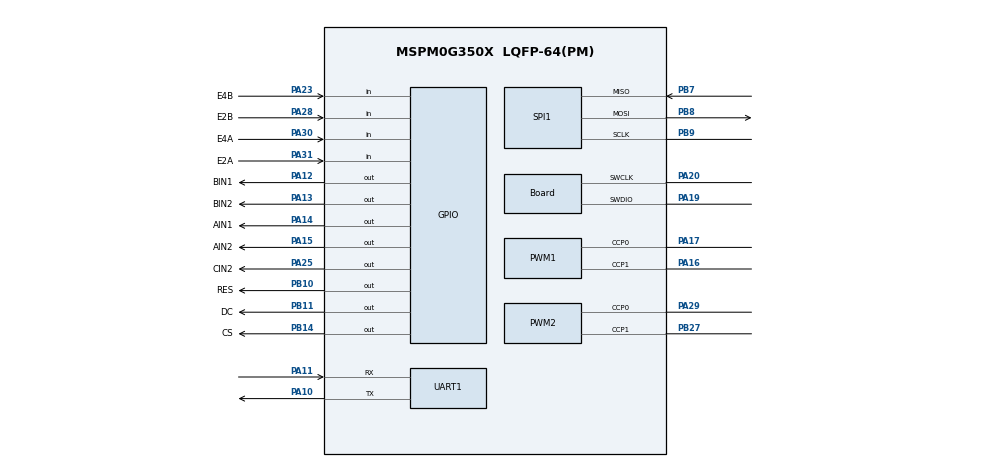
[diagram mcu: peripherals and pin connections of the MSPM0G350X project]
/**
 * @cliArgs --device "MSPM0G350X" --package "LQFP-64(PM)" --part "Default" --product "mspm0_sdk@1.30.00.03"
 * @versions {"tool":"1.19.0+3426"}
 */

/**
 * Import the modules used in this configuration.
 */
const GPIO          = scripting.addModule("/ti/driverlib/GPIO", {}, false);
const GPIO1         = GPIO.addInstance();
const GPIO2         = GPIO.addInstance();
const GPIO3         = GPIO.addInstance();
const GPIO4         = GPIO.addInstance();
const GPIO5         = GPIO.addInstance();
const PWM           = scripting.addModule("/ti/driverlib/PWM", {}, false);
const PWM1          = PWM.addInstance();
const PWM2          = PWM.addInstance();
const SPI           = scripting.addModule("/ti/driverlib/SPI", {}, false);
const SPI1          = SPI.addInstance();
const SYSCTL        = scripting.addModule("/ti/driverlib/SYSCTL");
const TIMER         = scripting.addModule("/ti/driverlib/TIMER", {}, false);
const TIMER1        = TIMER.addInstance();
const UART          = scripting.addModule("/ti/driverlib/UART", {}, false);
const UART1         = UART.addInstance();
const ProjectConfig = scripting.addModule("/ti/project_config/ProjectConfig");

/**
 * Write custom configuration values to the imported modules.
 */
const gate7  = system.clockTree["MFCLKGATE"];
gate7.enable = true;

GPIO1.$name                          = "LED";
GPIO1.associatedPins.create(3);
GPIO1.associatedPins[0].$name        = "LEDR";
GPIO1.associatedPins[0].assignedPort = "PORTB";
GPIO1.associatedPins[0].assignedPin  = "18";
GPIO1.associatedPins[1].$name        = "LEDG";
GPIO1.associatedPins[1].assignedPort = "PORTB";
GPIO1.associatedPins[1].assignedPin  = "19";
GPIO1.associatedPins[2].$name        = "LEDB";
GPIO1.associatedPins[2].assignedPort = "PORTB";
GPIO1.associatedPins[2].assignedPin  = "22";

const Board                       = scripting.addModule("/ti/driverlib/Board", {}, false);
Board.peripheral.$assign          = "DEBUGSS";
Board.peripheral.swclkPin.$assign = "PA20";
Board.peripheral.swdioPin.$assign = "PA19";

GPIO2.$name                          = "KEY";
GPIO2.associatedPins[0].$name        = "KEY1";
GPIO2.associatedPins[0].assignedPort = "PORTB";
GPIO2.associatedPins[0].assignedPin  = "21";
GPIO2.associatedPins[0].direction    = "INPUT";

GPIO3.$name                         = "OLED";
GPIO3.port                          = "PORTB";
GPIO3.associatedPins.create(3);
GPIO3.associatedPins[0].$name       = "RES";
GPIO3.associatedPins[0].ioStructure = "SD";
GPIO3.associatedPins[0].assignedPin = "10";
GPIO3.associatedPins[0].pin.$assign = "PB10";
GPIO3.associatedPins[1].$name       = "DC";
GPIO3.associatedPins[1].ioStructure = "SD";
GPIO3.associatedPins[1].assignedPin = "11";
GPIO3.associatedPins[1].pin.$assign = "PB11";
GPIO3.associatedPins[2].$name       = "CS";
GPIO3.associatedPins[2].ioStructure = "SD";
GPIO3.associatedPins[2].assignedPin = "14";
GPIO3.associatedPins[2].pin.$assign = "PB14";

GPIO4.$name                          = "TB6612";
GPIO4.port                           = "PORTA";
GPIO4.associatedPins.create(8);
GPIO4.associatedPins[0].$name        = "AIN1";
GPIO4.associatedPins[0].initialValue = "SET";
GPIO4.associatedPins[0].assignedPin  = "14";
GPIO4.associatedPins[0].pin.$assign  = "PA14";
GPIO4.associatedPins[1].$name        = "AIN2";
GPIO4.associatedPins[1].initialValue = "SET";
GPIO4.associatedPins[1].assignedPin  = "15";
GPIO4.associatedPins[1].pin.$assign  = "PA15";
GPIO4.associatedPins[2].$name        = "BIN1";
GPIO4.associatedPins[2].initialValue = "SET";
GPIO4.associatedPins[2].assignedPin  = "12";
GPIO4.associatedPins[2].pin.$assign  = "PA12";
GPIO4.associatedPins[3].$name        = "BIN2";
GPIO4.associatedPins[3].assignedPin  = "13";
GPIO4.associatedPins[3].initialValue = "SET";
GPIO4.associatedPins[3].pin.$assign  = "PA13";
GPIO4.associatedPins[4].$name        = "CIN1";
GPIO4.associatedPins[4].initialValue = "SET";
GPIO4.associatedPins[4].assignedPin  = "24";
GPIO4.associatedPins[5].$name        = "CIN2";
GPIO4.associatedPins[5].initialValue = "SET";
GPIO4.associatedPins[5].assignedPin  = "25";
GPIO4.associatedPins[5].pin.$assign  = "PA25";
GPIO4.associatedPins[6].$name        = "DIN1";
GPIO4.associatedPins[6].initialValue = "SET";
GPIO4.associatedPins[6].assignedPin  = "8";
GPIO4.associatedPins[7].$name        = "DIN2";
GPIO4.associatedPins[7].initialValue = "SET";
GPIO4.associatedPins[7].assignedPin  = "9";

GPIO5.$name                               = "ENCODER";
GPIO5.port                                = "PORTA";
GPIO5.associatedPins.create(8);
GPIO5.associatedPins[0].$name             = "E1A";
GPIO5.associatedPins[0].direction         = "INPUT";
GPIO5.associatedPins[0].assignedPin       = "27";
GPIO5.associatedPins[0].interruptEn       = true;
GPIO5.associatedPins[0].interruptPriority = "0";
GPIO5.associatedPins[0].polarity          = "RISE";
GPIO5.associatedPins[1].$name             = "E1B";
GPIO5.associatedPins[1].direction         = "INPUT";
GPIO5.associatedPins[1].assignedPin       = "26";
GPIO5.associatedPins[1].interruptEn       = true;
GPIO5.associatedPins[1].interruptPriority = "0";
GPIO5.associatedPins[1].polarity          = "RISE";
GPIO5.associatedPins[2].$name             = "E2A";
GPIO5.associatedPins[2].direction         = "INPUT";
GPIO5.associatedPins[2].assignedPin       = "31";
GPIO5.associatedPins[2].interruptEn       = true;
GPIO5.associatedPins[2].interruptPriority = "0";
GPIO5.associatedPins[2].polarity          = "RISE";
GPIO5.associatedPins[2].pin.$assign       = "PA31";
GPIO5.associatedPins[3].$name             = "E2B";
GPIO5.associatedPins[3].direction         = "INPUT";
GPIO5.associatedPins[3].assignedPin       = "28";
GPIO5.associatedPins[3].interruptEn       = true;
GPIO5.associatedPins[3].interruptPriority = "0";
GPIO5.associatedPins[3].polarity          = "RISE";
GPIO5.associatedPins[3].pin.$assign       = "PA28";
GPIO5.associatedPins[4].$name             = "E3A";
GPIO5.associatedPins[4].direction         = "INPUT";
GPIO5.associatedPins[4].interruptEn       = true;
GPIO5.associatedPins[4].interruptPriority = "0";
GPIO5.associatedPins[4].polarity          = "RISE";
GPIO5.associatedPins[4].assignedPin       = "7";
GPIO5.associatedPins[5].$name             = "E3B";
GPIO5.associatedPins[5].direction         = "INPUT";
GPIO5.associatedPins[5].interruptEn       = true;
GPIO5.associatedPins[5].interruptPriority = "0";
GPIO5.associatedPins[5].polarity          = "RISE";
GPIO5.associatedPins[5].assignedPin       = "18";
GPIO5.associatedPins[6].$name             = "E4A";
GPIO5.associatedPins[6].direction         = "INPUT";
GPIO5.associatedPins[6].interruptEn       = true;
GPIO5.associatedPins[6].interruptPriority = "0";
GPIO5.associatedPins[6].polarity          = "RISE";
GPIO5.associatedPins[6].assignedPin       = "30";
GPIO5.associatedPins[6].pin.$assign       = "PA30";
GPIO5.associatedPins[7].$name             = "E4B";
GPIO5.associatedPins[7].direction         = "INPUT";
GPIO5.associatedPins[7].interruptEn       = true;
GPIO5.associatedPins[7].interruptPriority = "0";
GPIO5.associatedPins[7].polarity          = "RISE";
GPIO5.associatedPins[7].assignedPin       = "23";
GPIO5.associatedPins[7].pin.$assign       = "PA23";

PWM1.$name                      = "PWM_0";
PWM1.clockDivider               = 8;
PWM1.timerStartTimer            = true;
PWM1.peripheral.$assign         = "TIMA1";
PWM1.peripheral.ccp0Pin.$assign = "PA17";
PWM1.peripheral.ccp1Pin.$assign = "PA16";
PWM1.PWM_CHANNEL_0.$name        = "ti_driverlib_pwm_PWMTimerCC0";
PWM1.PWM_CHANNEL_0.invert       = true;
PWM1.PWM_CHANNEL_1.$name        = "ti_driverlib_pwm_PWMTimerCC1";
PWM1.PWM_CHANNEL_1.invert       = true;
PWM1.ccp0PinConfig.$name        = "ti_driverlib_gpio_GPIOPinGeneric5";
PWM1.ccp1PinConfig.$name        = "ti_driverlib_gpio_GPIOPinGeneric6";

PWM2.$name                      = "PWM_1";
PWM2.clockDivider               = 8;
PWM2.timerStartTimer            = true;
PWM2.peripheral.$assign         = "TIMG6";
PWM2.peripheral.ccp0Pin.$assign = "PA29";
PWM2.peripheral.ccp1Pin.$assign = "PB27";
PWM2.PWM_CHANNEL_0.$name        = "ti_driverlib_pwm_PWMTimerCC2";
PWM2.PWM_CHANNEL_0.invert       = true;
PWM2.PWM_CHANNEL_1.$name        = "ti_driverlib_pwm_PWMTimerCC3";
PWM2.PWM_CHANNEL_1.invert       = true;
PWM2.ccp0PinConfig.$name        = "ti_driverlib_gpio_GPIOPinGeneric7";
PWM2.ccp1PinConfig.$name        = "ti_driverlib_gpio_GPIOPinGeneric8";

SPI1.$name                              = "SPI_OLED";
SPI1.frameFormat                        = "MOTO3";
SPI1.polarity                           = "1";
SPI1.peripheral.$assign                 = "SPI1";
SPI1.peripheral.sclkPin.$assign         = "PB9";
SPI1.peripheral.mosiPin.$assign         = "PB8";
SPI1.peripheral.misoPin.$assign         = "PB7";
SPI1.sclkPinConfig.direction            = scripting.forceWrite("OUTPUT");
SPI1.sclkPinConfig.onlyInternalResistor = scripting.forceWrite(false);
SPI1.sclkPinConfig.passedPeripheralType = scripting.forceWrite("Digital");
SPI1.sclkPinConfig.$name                = "ti_driverlib_gpio_GPIOPinGeneric2";
SPI1.mosiPinConfig.direction            = scripting.forceWrite("OUTPUT");
SPI1.mosiPinConfig.hideOutputInversion  = scripting.forceWrite(false);
SPI1.mosiPinConfig.onlyInternalResistor = scripting.forceWrite(false);
SPI1.mosiPinConfig.passedPeripheralType = scripting.forceWrite("Digital");
SPI1.mosiPinConfig.$name                = "ti_driverlib_gpio_GPIOPinGeneric3";
SPI1.misoPinConfig.onlyInternalResistor = scripting.forceWrite(false);
SPI1.misoPinConfig.passedPeripheralType = scripting.forceWrite("Digital");
SPI1.misoPinConfig.$name                = "ti_driverlib_gpio_GPIOPinGeneric4";

SYSCTL.clockTreeEn = true;

TIMER1.$name              = "TIMER_0";
TIMER1.timerMode          = "PERIODIC_UP";
TIMER1.interrupts         = ["ZERO"];
TIMER1.timerStartTimer    = true;
TIMER1.interruptPriority  = "2";
TIMER1.timerClkDiv        = 8;
TIMER1.timerPeriod        = "10ms";
TIMER1.peripheral.$assign = "TIMG0";

UART1.$name                    = "UART_0";
UART1.enabledInterrupts        = ["RX"];
UART1.targetBaudRate           = 115200;
UART1.uartClkSrc               = "MFCLK";
UART1.peripheral.rxPin.$assign = "PA11";
UART1.peripheral.txPin.$assign = "PA10";
UART1.txPinConfig.$name        = "ti_driverlib_gpio_GPIOPinGeneric0";
UART1.rxPinConfig.$name        = "ti_driverlib_gpio_GPIOPinGeneric1";

ProjectConfig.deviceSpin = "MSPM0G3507";
scripting.suppress("Migrating requires going through the Switch Board or Device menu in the Device View section\\.", ProjectConfig, "deviceSpin");

/**
 * Pinmux solution for unlocked pins/peripherals. This ensures that minor changes to the automatic solver in a future
 * version of the tool will not impact the pinmux you originally saw.  These lines can be completely deleted in order to
 * re-solve from scratch.
 */
GPIO1.associatedPins[0].pin.$suggestSolution = "PB18";
GPIO1.associatedPins[1].pin.$suggestSolution = "PB19";
GPIO1.associatedPins[2].pin.$suggestSolution = "PB22";
GPIO2.associatedPins[0].pin.$suggestSolution = "PB21";
GPIO4.associatedPins[4].pin.$suggestSolution = "PA24";
GPIO4.associatedPins[6].pin.$suggestSolution = "PA8";
GPIO4.associatedPins[7].pin.$suggestSolution = "PA9";
GPIO5.associatedPins[0].pin.$suggestSolution = "PA27";
GPIO5.associatedPins[1].pin.$suggestSolution = "PA26";
GPIO5.associatedPins[4].pin.$suggestSolution = "PA7";
GPIO5.associatedPins[5].pin.$suggestSolution = "PA18";
UART1.peripheral.$suggestSolution            = "UART0";
